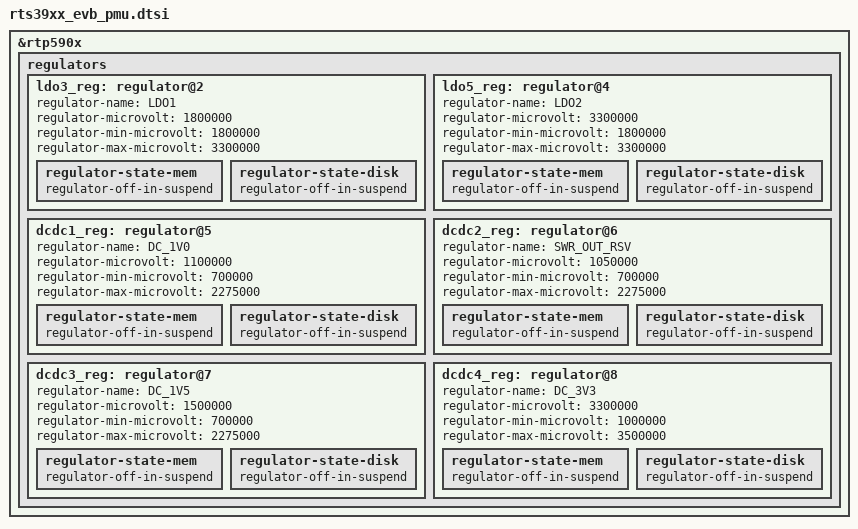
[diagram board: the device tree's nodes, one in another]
/include/ "rtp590x.dtsi"
&rtp590x{
	status = "okay";
/*	rtp5903,system-power-controller; */

	regulators {

		ldo3_reg: regulator@2 {
			regulator-name= "LDO1";
			regulator-microvolt = <1800000>;
			regulator-min-microvolt = <1800000>;
			regulator-max-microvolt = <3300000>;
			regulator-state-mem {
				regulator-off-in-suspend;
			};
			regulator-state-disk {
				regulator-off-in-suspend;
			};
		};

		ldo5_reg: regulator@4 {
			regulator-name= "LDO2";
			regulator-microvolt = <3300000>;
			regulator-min-microvolt = <1800000>;
			regulator-max-microvolt = <3300000>;
			regulator-state-mem {
				regulator-off-in-suspend;
			};
			regulator-state-disk {
				regulator-off-in-suspend;
			};
		};

		dcdc1_reg: regulator@5 {
			regulator-name= "DC_1V0";
			regulator-microvolt = <1100000>;
			regulator-min-microvolt = <700000>;
			regulator-max-microvolt = <2275000>;
			regulator-state-mem {
				regulator-off-in-suspend;
			};
			regulator-state-disk {
				regulator-off-in-suspend;
			};
		};

		dcdc2_reg: regulator@6 {
			regulator-name= "SWR_OUT_RSV";
			regulator-microvolt = <1050000>;
			regulator-min-microvolt = <700000>;
			regulator-max-microvolt = <2275000>;
			regulator-state-mem {
				regulator-off-in-suspend;
			};
			regulator-state-disk {
				regulator-off-in-suspend;
			};
		};

		dcdc3_reg: regulator@7 {
			regulator-name= "DC_1V5";
			regulator-microvolt = <1500000>;
			regulator-min-microvolt = <700000>;
			regulator-max-microvolt = <2275000>;
			regulator-state-mem {
				regulator-off-in-suspend;
			};
			regulator-state-disk {
				regulator-off-in-suspend;
			};
		};

		dcdc4_reg: regulator@8 {
			regulator-name= "DC_3V3";
			regulator-microvolt = <3300000>;
			/*spec: min-uV == 1700000 */
			regulator-min-microvolt = <1000000>;
			regulator-max-microvolt = <3500000>;
			regulator-state-mem {
				regulator-off-in-suspend;
			};
			regulator-state-disk {
				regulator-off-in-suspend;
			};
		};
	};
};
